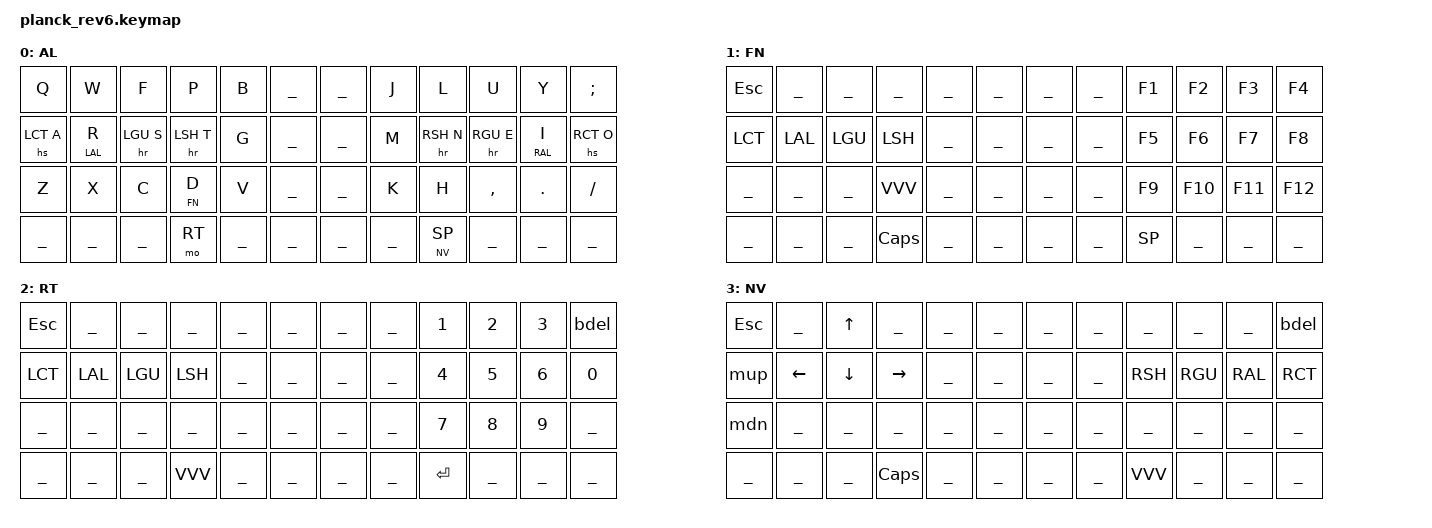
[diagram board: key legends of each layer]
/*
* Copyright (c) 2020 The ZMK Contributors
*
* SPDX-License-Identifier: MIT
*/

/*
        TR1 TR2 TR3 TR4 TR5 --- --- TR8 TR9 TR10 TR11 TR12
        MR1 MR2 MR3 MR4 MR5 --- --- MR8 MR9 MR10 MR11 MR12
        BR1 BR2 BR3 BR4 BR5 --- --- BR8 BR9 BR10 BR11 BR12
        --- --- TH3 TH4 TH5 --- --- TH8 TH9 TH10 ---- ----
*/

/* INCLUDES */
#include <behaviors.dtsi>
#include <dt-bindings/zmk/keys.h>

#include "../zmk-nodefree-config/helper.h"
#include "../zmk-nodefree-config/keypos_48keys.h"

/* KEYS */
// left hand top row only
ZMK_COMBO(combo_grave, &kp GRAVE, TR1 TR2, AL, COMBO_SLOW)
ZMK_COMBO(combo_esc, &kp ESC, TR1 TR2 TR3, AL, COMBO_SLOW)
ZMK_COMBO(combo_minus, &kp MINUS, TR2 TR3, AL RT NV, COMBO_NORM)
ZMK_COMBO(combo_equal, &kp EQUAL, TR3 TR4, AL RT NV, COMBO_NORM)

// left hand middle row only


// left hand bottom row only
ZMK_COMBO(combo_tab, &kp TAB, BR3 BR4, AL, COMBO_SLOW)

// left hand diagonal combos
ZMK_COMBO(combo_lt,   &kp LT,   MR4 TR1, AL, COMBO_NORM)
ZMK_COMBO(combo_lbkt, &kp LBKT, MR4 TR2, AL, COMBO_SLOW)
ZMK_COMBO(combo_lbrc, &kp LBRC, MR4 TR3, AL, COMBO_NORM)
ZMK_COMBO(combo_lpar, &kp LPAR, MR3 BR4, AL, COMBO_NORM)

// right hand top row only
ZMK_COMBO(combo_sqt, &kp SQT, TR9 TR10, AL RT NV, COMBO_NORM)
ZMK_COMBO(combo_bslh, &kp BSLH, TR10 TR11, AL RT NV, COMBO_NORM)

// right hand middle row only


// right hand bottom row only
ZMK_COMBO(combo_dot, &kp DOT, BR10 BR11, AL RT, COMBO_NORM)
ZMK_COMBO(combo_comma, &kp COMMA, BR9 BR10, AL RT, COMBO_NORM)
ZMK_COMBO(combo_fslh, &kp FSLH, BR9 BR11, AL RT, COMBO_NORM)

// right hand diagonal combos
ZMK_COMBO(combo_rbrc, &kp RBRC, MR9 TR10, AL, COMBO_NORM)
ZMK_COMBO(combo_rbkt, &kp RBKT, MR9 TR11, AL, COMBO_SLOW)
ZMK_COMBO(combo_gt,   &kp GT,   MR9 TR12, AL, COMBO_NORM)
ZMK_COMBO(combo_rpar, &kp RPAR, BR9 MR10, AL, COMBO_NORM)

/* BEHAVIORS */
ZMK_BEHAVIOR(mup, mod_morph, mods = <(MOD_RSFT)>; bindings = <&kp C_VOL_UP>, <&kp F15>;)
ZMK_BEHAVIOR(mdn, mod_morph, mods = <(MOD_RSFT)>; bindings = <&kp C_VOL_DN>, <&kp F14>;)
ZMK_BEHAVIOR(bdel, mod_morph, mods = <(MOD_LSFT)>; bindings = <&kp BSPC>, <&kp DELETE>;)
ZMK_BEHAVIOR(bspc_del, hold_tap,
    flavor = "tap-preferred";
    tapping-term-ms = <200>;
    quick-tap-ms = <150>;
    bindings = <&bdel>, <&kp>;)

/* HOME ROW MODS FAST SPEED */
ZMK_BEHAVIOR(hr, hold_tap,
    flavor = "tap-preferred";
    tapping-term-ms = <150>;
    quick-tap-ms = <125>; // repeat on tap-into-hold
    bindings = <&kp>, <&kp>;
)

/* HOME ROW MODS MEDIUM SPEED */
ZMK_BEHAVIOR(hm, hold_tap,
    flavor = "tap-preferred";
    tapping-term-ms = <333>;
    quick-tap-ms = <125>; // repeat on tap-into-hold
    bindings = <&kp>, <&kp>;
)

/* HOME ROW MODS SLOW SPEED */
ZMK_BEHAVIOR(hs, hold_tap,
    flavor = "tap-preferred";
    tapping-term-ms = <500>;
    quick-tap-ms = <250>; // repeat on tap-into-hold
    bindings = <&kp>, <&kp>;
)

/* LAYERS */
ZMK_LAYER(AL,
&kp Q      &kp W      &kp F     &kp P      &kp B  ___ ___  &kp J  &kp L      &kp U      &kp Y      &kp SEMI
&hs LCT A  &hm LAL R  &hr LGU S &hr LSH T  &kp G  ___ ___  &kp M  &hr RSH N  &hr RGU E  &hm RAL I  &hs RCT O
&kp Z      &kp X      &kp C     &lt FN D   &kp V  ___ ___  &kp K  &kp H      &kp COMMA  &kp DOT    &kp FSLH
___        ___        ___       &mo RT     ___    ___ ___  ___    &lt NV SP  ___        ___        ___
)

ZMK_LAYER(FN,
&kp ESC    ___        ___       ___        ___    ___ ___  ___    &kp F1     &kp F2     &kp F3     &kp F4
&kp LCT    &kp LAL    &kp LGU   &kp LSH    ___    ___ ___  ___    &kp F5     &kp F6     &kp F7     &kp F8
___        ___        ___       VVV        ___    ___ ___  ___    &kp F9     &kp F10    &kp F11    &kp F12
___        ___        ___       &kp CAPS   ___    ___ ___  ___    &kp SP     ___        ___        ___
)

ZMK_LAYER(RT,
&kp ESC    ___        ___       ___        ___    ___ ___  ___    &kp N1     &kp N2     &kp N3     &bdel
&kp LCT    &kp LAL    &kp LGU   &kp LSH    ___    ___ ___  ___    &kp N4     &kp N5     &kp N6     &kp N0
___        ___        ___       ___        ___    ___ ___  ___    &kp N7     &kp N8     &kp N9     ___
___        ___        ___       VVV        ___    ___ ___  ___    &kp RET    ___        ___        ___
)

ZMK_LAYER(NV,
&kp ESC    ___        &kp UP    ___        ___    ___ ___  ___    ___       ___        ___        &bdel
&mup       &kp LEFT   &kp DOWN  &kp RIGHT  ___    ___ ___  ___    &kp RSH   &kp RGU    &kp RAL    &kp RCT
&mdn       ___        ___       ___        ___    ___ ___  ___    ___       ___        ___        ___
___        ___        ___       &kp CAPS   ___    ___ ___  ___    VVV       ___        ___        ___
)
